# M365 register map
File version: 0.1
CPU: 
Registers are 32-bit, read-write, reset 0x0 unless marked. A register's access mark holds for its fields unless they carry their own. Offsets are from the block's base; [hi:lo] are bit positions; {n}, {i} and the like mark numbered series.

## PC — General Purpose Input_Output Port (PC)
Base 0x400C0200
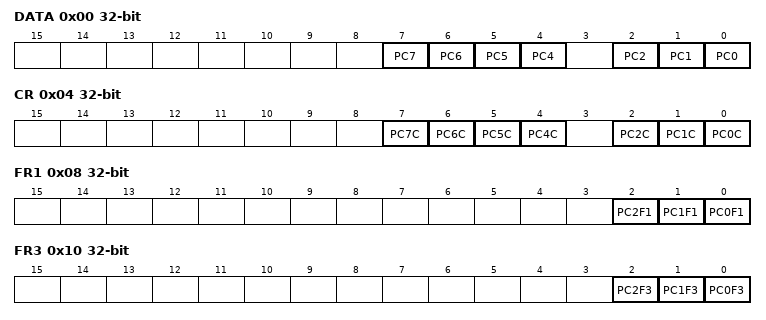
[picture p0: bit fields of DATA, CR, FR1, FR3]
0x00 DATA — PC Data Register
  [n] PC{n} (n=4..7), [2] PC2, [1] PC1, [0] PC0
0x04 CR — PC Control Register
  [n] PC{n}C (n=4..7), [2] PC2C, [1] PC1C, [0] PC0C
0x08 FR1 — PC Function Register 1
  [2] PC2F1, [1] PC1F1, [0] PC0F1
0x10 FR3 — PC Function Register 3
  [2] PC2F3, [1] PC1F3, [0] PC0F3
0x14 FR4 — PC Function Register 4
  [2] PC2F4
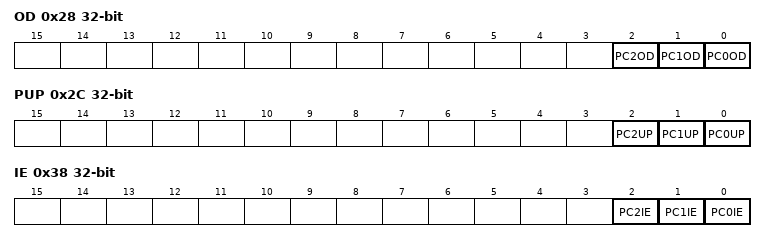
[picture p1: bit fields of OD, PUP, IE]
0x28 OD — PC Open Drain Control Register
  [2] PC2OD, [1] PC1OD, [0] PC0OD
0x2C PUP — PC Pull-Up Control Register
  [2] PC2UP, [1] PC1UP, [0] PC0UP
0x38 IE — PC Input Enable Control Register
  [2] PC2IE, [1] PC1IE, [0] PC0IE

## PD — General Purpose Input_Output Port (PD)
Base 0x400C0300
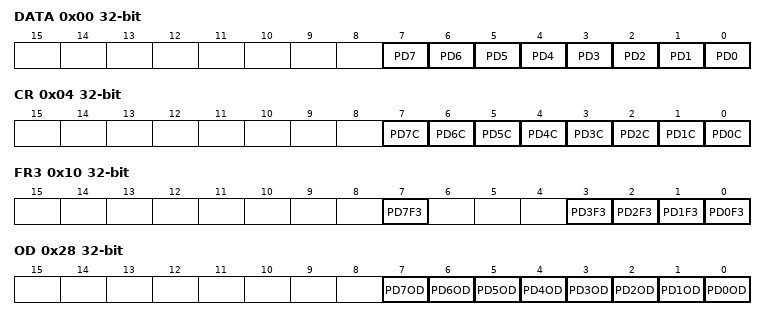
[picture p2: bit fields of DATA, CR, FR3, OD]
0x00 DATA — PD Data Register
  [n] PD{n} (n=0..7)
0x04 CR — PD Control Register
  [n] PD{n}C (n=0..7)
0x10 FR3 — PD Function Register 3
  [7] PD7F3, [n] PD{n}F3 (n=0..3)
0x28 OD — PD Open Drain Control Register
  [n] PD{n}OD (n=0..7)
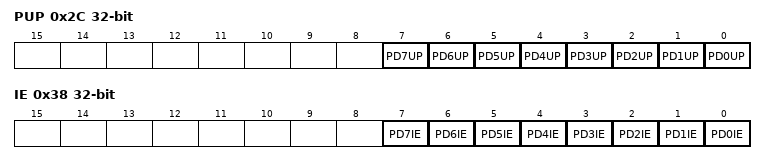
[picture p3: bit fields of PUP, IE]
0x2C PUP — PD Pull-Up Control Register
  [n] PD{n}UP (n=0..7)
0x38 IE — PD Input Enable Control Register
  [n] PD{n}IE (n=0..7)

## PE — General Purpose Input_Output Port (PE)
Base 0x400C0400
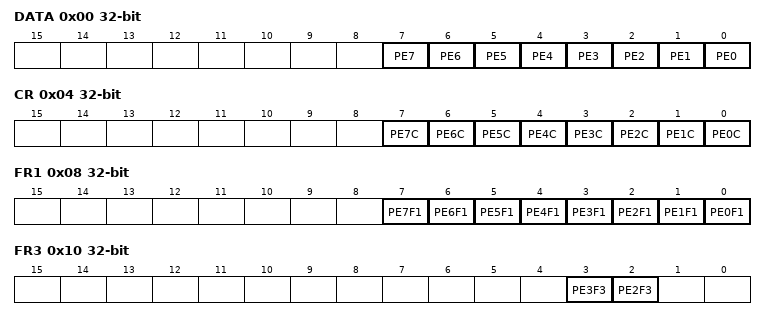
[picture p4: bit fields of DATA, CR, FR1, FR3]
0x00 DATA — PE Data Register
  [n] PE{n} (n=0..7)
0x04 CR — PE Control Register
  [n] PE{n}C (n=0..7)
0x08 FR1 — PE Function Register 1
  [n] PE{n}F1 (n=0..7)
0x10 FR3 — PE Function Register 3
  [3] PE3F3, [2] PE2F3
0x14 FR4 — PE Function Register 4
  [2] PE2F4
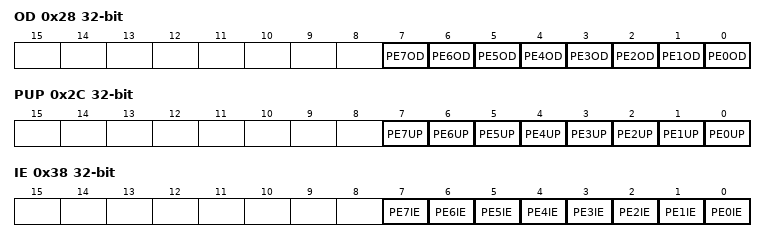
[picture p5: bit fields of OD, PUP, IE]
0x28 OD — PE Open Drain Control Register
  [n] PE{n}OD (n=0..7)
0x2C PUP — PE Pull-Up Control Register
  [n] PE{n}UP (n=0..7)
0x38 IE — PE Input Enable Control Register
  [n] PE{n}IE (n=0..7)

## PF — General Purpose Input_Output Port (PF)
Base 0x400C0500
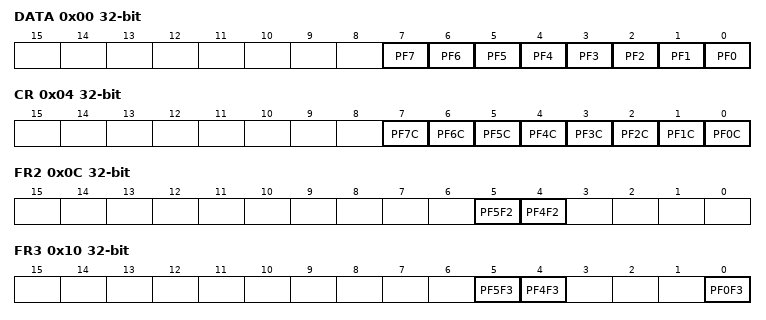
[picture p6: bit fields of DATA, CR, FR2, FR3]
0x00 DATA — PF Data Register
  [n] PF{n} (n=0..7)
0x04 CR — PF Control Register
  [n] PF{n}C (n=0..7)
0x0C FR2 — PF Function Register 2
  [5] PF5F2, [4] PF4F2
0x10 FR3 — PF Function Register 3
  [5] PF5F3, [4] PF4F3, [0] PF0F3
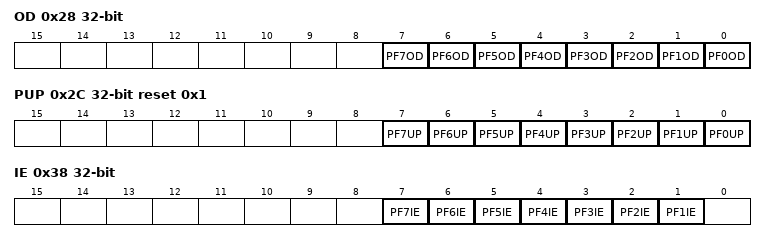
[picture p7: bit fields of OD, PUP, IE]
0x28 OD — PF Open Drain Control Register
  [n] PF{n}OD (n=0..7)
0x2C PUP reset 0x1 — PF Pull-Up Control Register
  [n] PF{n}UP (n=0..7)
0x38 IE — PF Input Enable Control Register
  [n] PF{n}IE (n=1..7)

## PG — General Purpose Input_Output Port (PG)
Base 0x400C0600
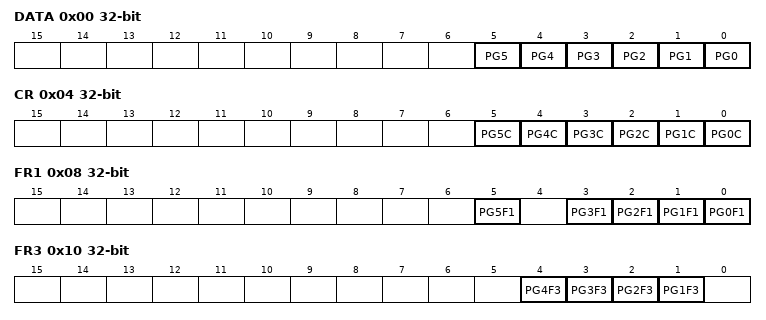
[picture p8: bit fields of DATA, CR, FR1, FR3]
0x00 DATA — PG Data Register
  [n] PG{n} (n=0..5)
0x04 CR — PG Control Register
  [n] PG{n}C (n=0..5)
0x08 FR1 — PG Function Register 2
  [5] PG5F1, [n] PG{n}F1 (n=0..3)
0x10 FR3 — PG Function Register 3
  [n] PG{n}F3 (n=1..4)
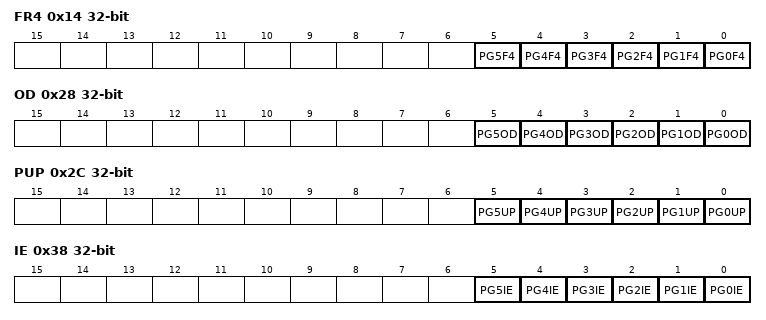
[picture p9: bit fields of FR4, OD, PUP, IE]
0x14 FR4 — PG Function Register 4
  [n] PG{n}F4 (n=0..5)
0x28 OD — PG Open Drain Control Register
  [n] PG{n}OD (n=0..5)
0x2C PUP — PG Pull-Up Control Register
  [n] PG{n}UP (n=0..5)
0x38 IE — PG Input Enable Control Register
  [n] PG{n}IE (n=0..5)

## PH — General Purpose Input_Output Port (PH)
Base 0x400C0700
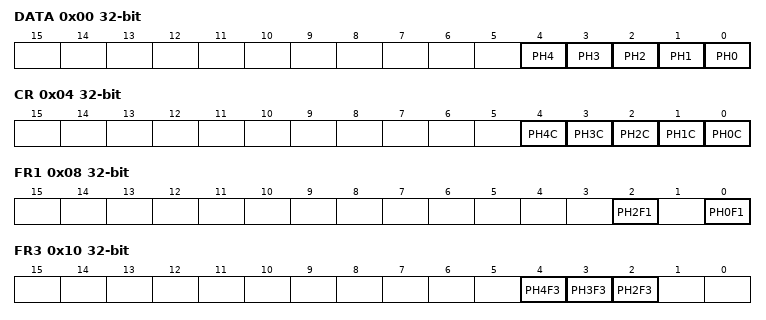
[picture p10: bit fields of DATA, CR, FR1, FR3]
0x00 DATA — PH Data Register
  [n] PH{n} (n=0..4)
0x04 CR — PH Control Register
  [n] PH{n}C (n=0..4)
0x08 FR1 — PH Function Register 1
  [2] PH2F1, [0] PH0F1
0x10 FR3 — PH Function Register 3
  [4] PH4F3, [3] PH3F3, [2] PH2F3
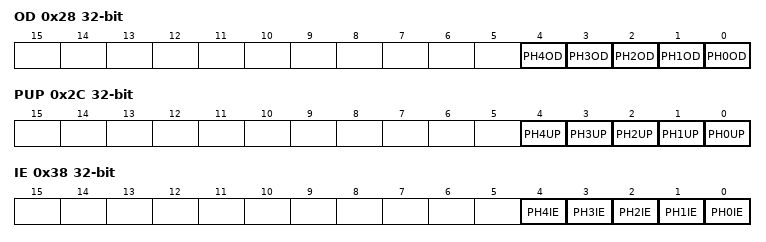
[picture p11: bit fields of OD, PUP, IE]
0x28 OD — PH Open Drain Control Register
  [n] PH{n}OD (n=0..4)
0x2C PUP — PH Pull-Up Control Register
  [n] PH{n}UP (n=0..4)
0x38 IE — PH Input Enable Control Register
  [n] PH{n}IE (n=0..4)

## PI — General Purpose Input_Output Port (PI)
Base 0x400C0800
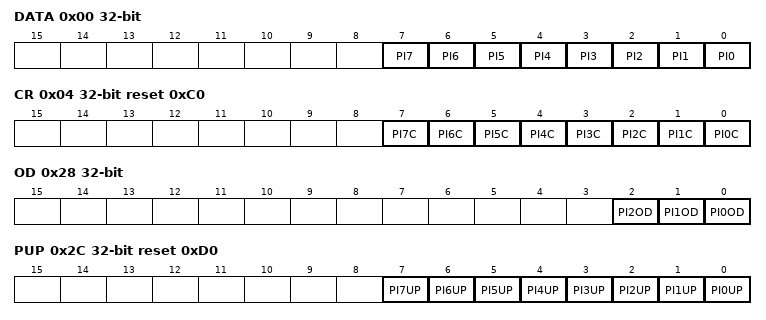
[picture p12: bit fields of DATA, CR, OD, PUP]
0x00 DATA — PI Data Register
  [n] PI{n} (n=0..7)
0x04 CR reset 0xC0 — PI Control Register
  [n] PI{n}C (n=0..7)
0x28 OD — PI Open Drain Control Register
  [2] PI2OD, [1] PI1OD, [0] PI0OD
0x2C PUP reset 0xD0 — PI Pull-Up Control Register
  [n] PI{n}UP (n=0..7)
0x30 PDN reset 0x8 — PI Pull-Down Control Register
  [3] PI3DN
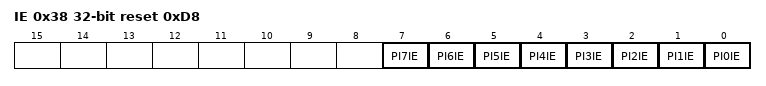
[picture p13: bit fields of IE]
0x38 IE reset 0xD8 — PI Input Enable Control Register
  [n] PI{n}IE (n=0..7)

## PJ — General Purpose Input_Output Port (PJ)
Base 0x400C0900
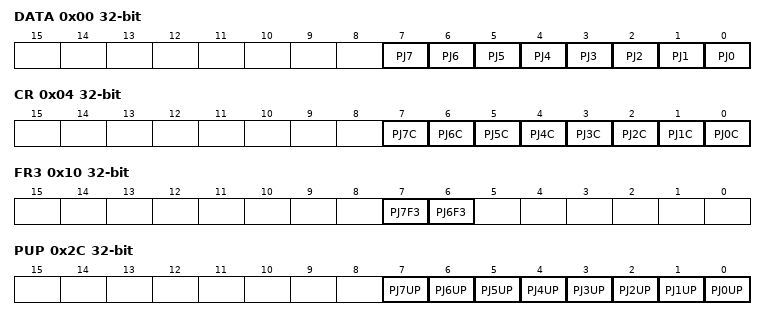
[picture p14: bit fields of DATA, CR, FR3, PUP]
0x00 DATA — PJ Data Register
  [n] PJ{n} (n=0..7)
0x04 CR — PJ Control Register
  [n] PJ{n}C (n=0..7)
0x0C FR2 — PJ Function Register 2
  [7] PJ7F2
0x10 FR3 — PJ Function Register 3
  [7] PJ7F3, [6] PJ6F3
0x2C PUP — PJ Pull-Up Control Register
  [n] PJ{n}UP (n=0..7)
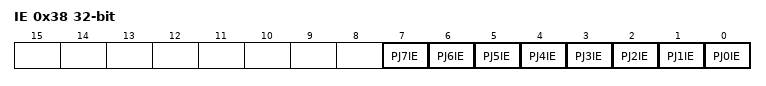
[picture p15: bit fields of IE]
0x38 IE — PJ Input Enable Control Register
  [n] PJ{n}IE (n=0..7)
